# XHSC_HC32F175 register map
Vendor: XHSC Co.Ltd; Series: ARMCM0P; File version: 1.0
CPU: CM0P r0p0, little endian, no MPU, no FPU, 3 interrupt priority bits
Registers are 32-bit, read-write, reset 0x0 unless marked. A register's access mark holds for its fields unless they carry their own. Offsets are from the block's base; lines under a group give offsets from that group; [hi:lo] are bit positions; {n}, {i} and the like mark numbered series; 'fields as' and 'values as' point back to an identical list; <NAME> marks a mode.

## Memory map
0x40000000 CTRIM size 0x2C
0x40000800 IWDT size 0x94
0x40000C00 WWDT size 0xC
0x40001000 RTC size 0x62
0x40001C00 DBGC size 0x4
0x40002400 USART0 size 0xF4 — desc USART
0x40002800 USART1 size 0xF4 — desc USART
0x40002C00 USART2 size 0xF4 — desc USART
0x40003800 LPUART0 size 0x28 — desc LPUART
0x40004000 SPI0 size 0x1C — desc SPI
0x40004800 I2C0 size 0x2C — desc I2C
0x40005000 LPTIM0 size 0x1C — desc LPTIM
0x40005800 GTIM0 size 0x44 — desc GTIM
0x40005C00 GTIM1 size 0x44 — desc GTIM
0x40006000 GTIM2 size 0x44 — desc GTIM
0x40006400 GTIM3 size 0x44 — desc GTIM
0x40006800 GTIM4 size 0x44 — desc GTIM
0x40006C00 GTIM5 size 0x44 — desc GTIM
0x40007400 LVD size 0x8
0x40007800 ADC size 0xCC
0x40008800 SPI1 size 0x1C — desc SPI
0x40009000 I2C1 size 0x2C — desc I2C
0x4000A000 USART3 size 0xF4 — desc USART
0x4000A400 USART4 size 0xF4 — desc USART
0x4000A800 USART5 size 0xF4 — desc USART
0x4000B400 LPUART1 size 0x28 — desc LPUART
0x4000C000 LPTIM1 size 0x1C — desc LPTIM
0x4000C800 GTIM6 size 0x44 — desc GTIM
0x4000CC00 GTIM7 size 0x44 — desc GTIM
0x4000D000 GTIM8 size 0x44 — desc GTIM
0x4000E400 ATIM3 size 0x64
0x40020000 GPIO size 0x84
0x40024000 EXTI size 0x44
0x40024800 DMAC size 0x50
0x40024C00 SRAM size 0x1C
0x40025000 SYSCTRL size 0xAC
0x40025100 CSU0 size 0x1C — desc CSU
0x40025120 CSU1 size 0x1C — desc CSU
0x40025140 CSU2 size 0x1C — desc CSU
0x40026400 EFM size 0x90
0x40026800 DFM size 0x40
0x40027800 CRC size 0x84

## ADC
Base 0x40007800
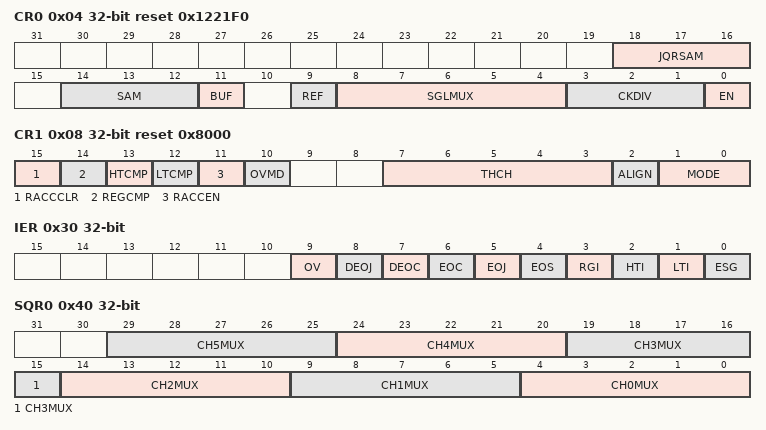
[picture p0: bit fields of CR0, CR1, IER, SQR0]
0x04 CR0 reset 0x1221F0
  [18:16] JQRSAM, [14:12] SAM, [11] BUF, [9] REF, [8:4] SGLMUX, [3:1] CKDIV, [0] EN
0x08 CR1 reset 0x8000
  [15] RACCCLR wo, [14] REGCMP, [13] HTCMP, [12] LTCMP, [11] RACCEN, [10] OVMD, [7:3] THCH, [2] ALIGN, [1:0] MODE
0x30 IER
  [9] OV, [8] DEOJ, [7] DEOC, [6] EOC, [5] EOJ, [4] EOS, [3] RGI, [2] HTI, [1] LTI, [0] ESG
0x40 SQR0
  [5n+4:5n] CH{n}MUX (n=0..5)
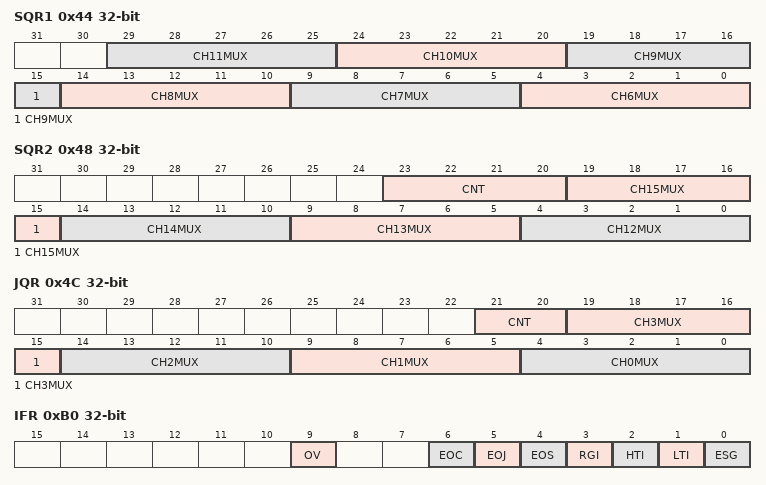
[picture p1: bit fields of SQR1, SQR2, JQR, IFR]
0x44 SQR1
  [5n-26:5n-30] CH{n}MUX (n=6..11)
0x48 SQR2
  [23:20] CNT, [5n-56:5n-60] CH{n}MUX (n=12..15)
0x4C JQR
  [21:20] CNT, [5n+4:5n] CH{n}MUX (n=0..3)
{0x50+4i} SQRRESULT{i} ro (i=0..3)
  [15:0] RESULT
{0x90+4i} JQRRESULT{i} ro (i=0..3)
  [15:0] RESULT
0xA0 RESULT ro
  [15:0] RESULT
0xA4 RESULTACC ro
  [19:0] RESULTACC
0xA8 HT reset 0xFFF
  [11:0] HT
0xAC LT
  [11:0] LT
0xB0 IFR ro
  [9] OV, [6] EOC, [5] EOJ, [4] EOS, [3] RGI, [2] HTI, [1] LTI, [0] ESG
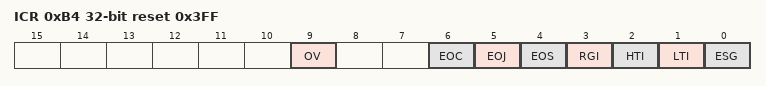
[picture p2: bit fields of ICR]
0xB4 ICR wo reset 0x3FF
  fields as IFR
0xB8 EXTTRIG0
  [4:0] TRIG
0xBC EXTTRIG1
  [4:0] TRIG
0xC0 SGLSTART
  [0] START
0xC4 SQRSTART
  [0] START
0xC8 JQRSTART
  [0] START

## ATIM3
Base 0x4000E400
0x00 ARR
  [15:0] ARR
0x04 CNT
  [15:0] CNT
0x08 CNT32
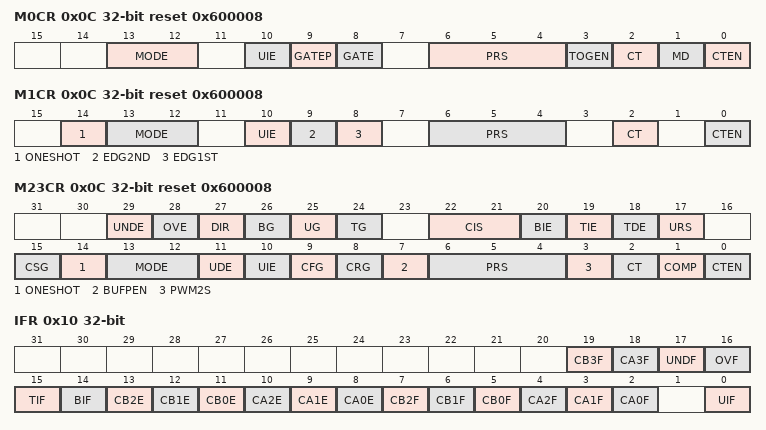
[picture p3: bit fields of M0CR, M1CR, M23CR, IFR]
0x0C M0CR reset 0x600008
  [13:12] MODE, [10] UIE, [9] GATEP, [8] GATE, [6:4] PRS, [3] TOGEN, [2] CT, [1] MD, [0] CTEN
0x0C M1CR reset 0x600008
  [14] ONESHOT, [13:12] MODE, [10] UIE, [9] EDG2ND, [8] EDG1ST, [6:4] PRS, [2] CT, [0] CTEN
0x0C M23CR reset 0x600008
  [29] UNDE, [28] OVE, [27] DIR, [26] BG wo, [25] UG wo, [24] TG wo, [22:21] CIS, [20] BIE, [19] TIE, [18] TDE, [17] URS, [15] CSG, [14] ONESHOT, [13:12] MODE, [11] UDE, [10] UIE, [9] CFG, [8] CRG, [7] BUFPEN, [6:4] PRS, [3] PWM2S, [2] CT, [1] COMP, [0] CTEN
0x10 IFR ro
  [19] CB3F, [18] CA3F, [17] UNDF, [16] OVF, [15] TIF, [14] BIF, [13] CB2E, [12] CB1E, [11] CB0E, [10] CA2E, [9] CA1E, [8] CA0E, [7] CB2F, [6] CB1F, [5] CB0F, [4] CA2F, [3] CA1F, [2] CA0F, [0] UIF
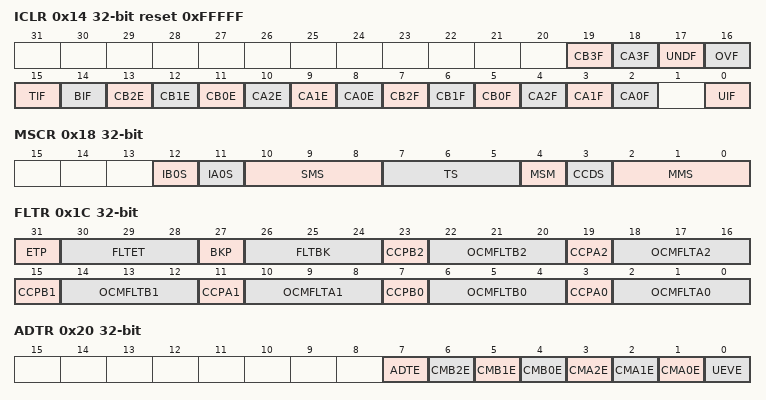
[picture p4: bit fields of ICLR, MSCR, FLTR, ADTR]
0x14 ICLR wo reset 0xFFFFF
  fields as IFR
0x18 MSCR
  [12] IB0S, [11] IA0S, [10:8] SMS, [7:5] TS, [4] MSM, [3] CCDS, [2:0] MMS
0x1C FLTR
  [31] ETP, [30:28] FLTET, [27] BKP, [26:24] FLTBK, [23] CCPB2, [22:20] OCMFLTB2, [19] CCPA2, [18:16] OCMFLTA2, [15] CCPB1, [14:12] OCMFLTB1, [11] CCPA1, [10:8] OCMFLTA1, [7] CCPB0, [6:4] OCMFLTB0, [3] CCPA0, [2:0] OCMFLTA0
0x20 ADTR
  [7] ADTE, [6] CMB2E, [5] CMB1E, [4] CMB0E, [3] CMA2E, [2] CMA1E, [1] CMA0E, [0] UEVE
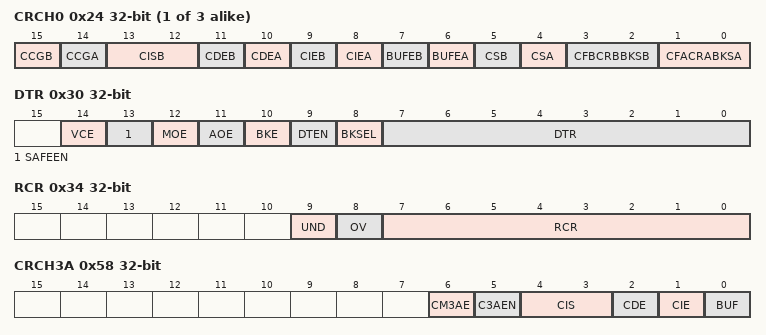
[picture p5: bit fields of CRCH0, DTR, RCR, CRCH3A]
{0x24+4i} CRCH{i} (i=0..2)
  [15] CCGB, [14] CCGA, [13:12] CISB, [11] CDEB, [10] CDEA, [9] CIEB, [8] CIEA, [7] BUFEB, [6] BUFEA, [5] CSB, [4] CSA, [3:2] CFBCRBBKSB, [1:0] CFACRABKSA
0x30 DTR
  [14] VCE, [13] SAFEEN, [12] MOE, [11] AOE, [10] BKE, [9] DTEN, [8] BKSEL, [7:0] DTR
0x34 RCR
  [9] UND, [8] OV, [7:0] RCR
0x38 ARRDM
  [15:0] ARRDM
{0x3C+8i} CCR{i}A (i=0..3)
  [15:0] CCR{i}A
{0x40+8i} CCR{i}B (i=0..2)
  [15:0] CCR{i}B
0x58 CRCH3A
  [6] CM3AE, [5] C3AEN, [4:3] CIS, [2] CDE, [1] CIE, [0] BUF
0x5C CCR3B
  [15:0] CCR3B
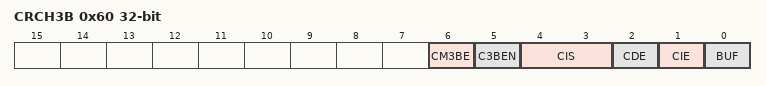
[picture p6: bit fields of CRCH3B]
0x60 CRCH3B
  [6] CM3BE, [5] C3BEN, [4:3] CIS, [2] CDE, [1] CIE, [0] BUF
